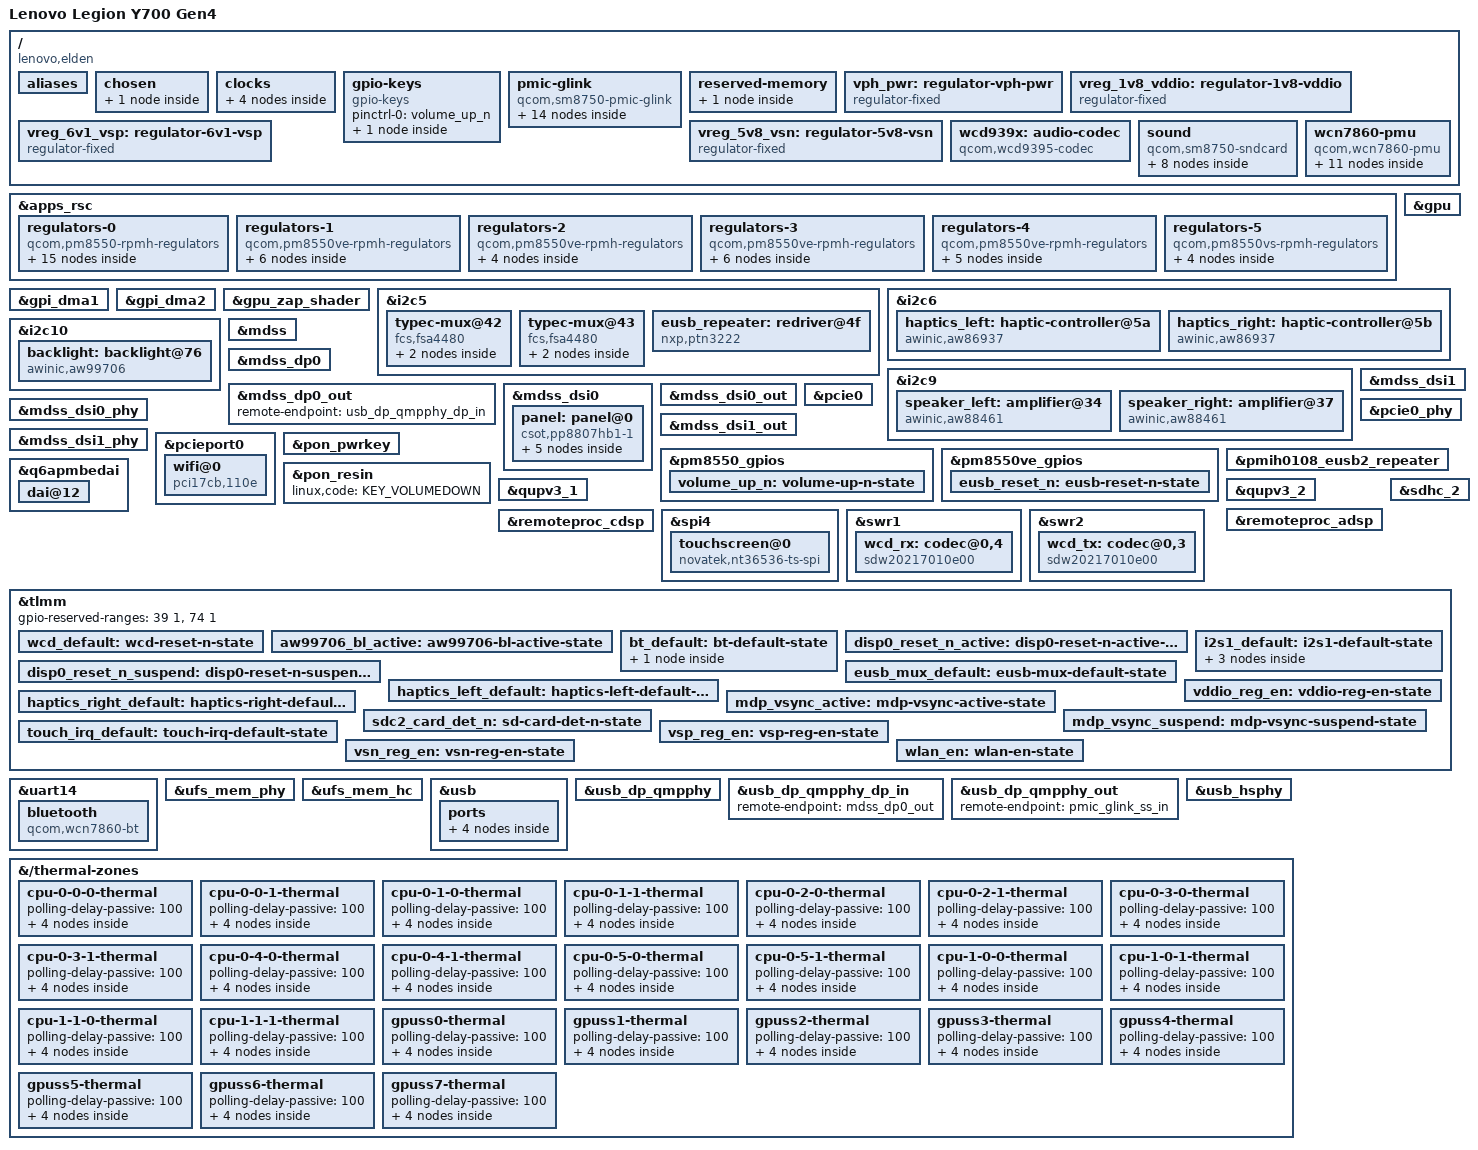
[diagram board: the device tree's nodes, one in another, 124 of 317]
// SPDX-License-Identifier: BSD-3-Clause
/*
 * Copyright (c) 2024 Qualcomm Innovation Center, Inc. All rights reserved.
 * Copyright (c) 2025-2026 Pengyu Luo <mitltlatltl@gmail.com>
 */

/*
 * based on https://lore.kernel.org/linux-arm-msm/20260726143048.130116-1-mitltlatltl@gmail.com/
 * with some modifications.
 */

/dts-v1/;

#include <dt-bindings/gpio/gpio.h>
#include <dt-bindings/phy/phy.h>
#include <dt-bindings/regulator/qcom,rpmh-regulator.h>
#include "sm8750.dtsi"
#include "pm8550.dtsi"
#define PMK8550VE_SID 8
#include "pm8550ve.dtsi"
#include "pmih0108.dtsi"
#include "pmk8550.dtsi"
#include "sm8750-pmics.dtsi"

/ {
	model = "Lenovo Legion Y700 Gen4";
	compatible = "lenovo,elden", "qcom,sm8750";
	chassis-type = "tablet";

	aliases {
		i2c5 = &i2c5;
		i2c6 = &i2c6;
		i2c9 = &i2c9;
		i2c10 = &i2c10;
		serial1 = &uart14;
	};

	/* mandatory, ABL requires the chosen node (not the fb) to boot */
	chosen {
		#address-cells = <2>;
		#size-cells = <2>;
		ranges;

		framebuffer: framebuffer@fc800000 {
			compatible = "simple-framebuffer";
			reg = <0x0 0xfc800000 0x0 0x2b00000>;
			width = <1904>;
			height = <3040>;
			stride = <(1904 * 4)>;
			format = "a8r8g8b8";
		};
	};

	clocks {
		xo_board: xo-board {
			compatible = "fixed-clock";
			clock-frequency = <76800000>;
			#clock-cells = <0>;
		};

		sleep_clk: sleep-clk {
			compatible = "fixed-clock";
			clock-frequency = <32000>;
			#clock-cells = <0>;
		};

		bi_tcxo_div2: bi-tcxo-div2-clk {
			compatible = "fixed-factor-clock";
			#clock-cells = <0>;

			clocks = <&rpmhcc RPMH_CXO_CLK>;
			clock-mult = <1>;
			clock-div = <2>;
		};

		bi_tcxo_ao_div2: bi-tcxo-ao-div2-clk {
			compatible = "fixed-factor-clock";
			#clock-cells = <0>;

			clocks = <&rpmhcc RPMH_CXO_CLK_A>;
			clock-mult = <1>;
			clock-div = <2>;
		};
	};

	gpio-keys {
		compatible = "gpio-keys";

		pinctrl-0 = <&volume_up_n>;
		pinctrl-names = "default";

		key-volume-up {
			label = "Volume Up";
			linux,code = <KEY_VOLUMEUP>;
			gpios = <&pm8550_gpios 6 GPIO_ACTIVE_LOW>;
			debounce-interval = <15>;
			linux,can-disable;
			wakeup-source;
		};
	};

	pmic-glink {
		compatible = "qcom,sm8750-pmic-glink",
			     "qcom,sm8550-pmic-glink",
			     "qcom,pmic-glink";
		#address-cells = <1>;
		#size-cells = <0>;
		orientation-gpios = <&tlmm 61 GPIO_ACTIVE_HIGH>;
		/* Firmware reports negative current while charging. */
		qcom,battery-current-inverted;

		/* Long edge */
		connector@0 {
			compatible = "usb-c-connector";
			reg = <0>;

			power-role = "dual";
			data-role = "dual";

			ports {
				#address-cells = <1>;
				#size-cells = <0>;

				port@0 {
					reg = <0>;

					pmic_glink_hs_in: endpoint {
						remote-endpoint = <&usb_dwc3_hs>;
					};
				};

				port@1 {
					reg = <1>;

					pmic_glink_ss_in: endpoint {
						remote-endpoint = <&usb_dp_qmpphy_out>;
					};
				};

				port@2 {
					reg = <2>;

					pmic_glink_sbu: endpoint {
						remote-endpoint = <&fsa4480_sbu_mux>;
					};
				};
			};
		};

		/* Short edge */
		connector@1 {
			compatible = "usb-c-connector";
			reg = <1>;

			power-role = "dual";
			data-role = "dual";

			ports {
				#address-cells = <1>;
				#size-cells = <0>;

				port@0 {
					reg = <0>;

					pmic_glink_hs_c2_in: endpoint {
						remote-endpoint = <&usb_dwc3_hs2>;
					};
				};

				port@1 {
					reg = <1>;

					pmic_glink_hs_sbu: endpoint {
						remote-endpoint = <&fsa4480_hs_sbu_mux>;
					};
				};
			};
		};
	};

	reserved-memory {
		/*
		 * Use this to tell the BL to initialize the display related
		 * resources, so we can use efifb. Please 's/-/_/'
		 */
		splash-region@fc800000 {
			reg = <0 0xfc800000 0 0x2b00000>;
			no-map;
		};
	};

	vph_pwr: regulator-vph-pwr {
		compatible = "regulator-fixed";

		regulator-name = "vph_pwr";
		regulator-min-microvolt = <3700000>;
		regulator-max-microvolt = <3700000>;

		regulator-always-on;
		regulator-boot-on;
	};

	vreg_1v8_vddio: regulator-1v8-vddio {
		compatible = "regulator-fixed";

		regulator-name = "vreg_1v8_vddio";
		regulator-min-microvolt = <1800000>;
		regulator-max-microvolt = <1800000>;

		gpio = <&tlmm 161 GPIO_ACTIVE_HIGH>;
		enable-active-high;

		pinctrl-0 = <&vddio_reg_en>;
		pinctrl-names = "default";

		regulator-always-on;
		regulator-boot-on;
	};

	vreg_6v1_vsp: regulator-6v1-vsp {
		compatible = "regulator-fixed";

		regulator-name = "vreg_6v1_vsp";
		regulator-min-microvolt = <6100000>;
		regulator-max-microvolt = <6100000>;

		gpio = <&tlmm 72 GPIO_ACTIVE_HIGH>;
		enable-active-high;

		pinctrl-0 = <&vsp_reg_en>;
		pinctrl-names = "default";

		regulator-always-on;
		regulator-boot-on;
	};

	vreg_5v8_vsn: regulator-5v8-vsn {
		compatible = "regulator-fixed";

		regulator-name = "vreg_5v8_vsn";
		regulator-min-microvolt = <5800000>;
		regulator-max-microvolt = <5800000>;

		gpio = <&tlmm 73 GPIO_ACTIVE_HIGH>;
		enable-active-high;

		pinctrl-0 = <&vsn_reg_en>;
		pinctrl-names = "default";

		regulator-always-on;
		regulator-boot-on;
	};

	wcd939x: audio-codec {
		compatible = "qcom,wcd9395-codec", "qcom,wcd9390-codec";
		pinctrl-0 = <&wcd_default>;
		pinctrl-names = "default";
		reset-gpios = <&tlmm 101 GPIO_ACTIVE_LOW>;

		vdd-buck-supply = <&vreg_l15b_1p8>;
		vdd-rxtx-supply = <&vreg_l15b_1p8>;
		vdd-io-supply = <&vreg_l15b_1p8>;
		vdd-px-supply = <&vreg_l15b_1p8>;
		vdd-mic-bias-supply = <&vreg_bob1>;

		/* Microphone bias voltages from the stock board configuration. */
		qcom,micbias1-microvolt = <2000000>;
		qcom,micbias2-microvolt = <2700000>;
		qcom,micbias3-microvolt = <1800000>;
		qcom,micbias4-microvolt = <2000000>;
		qcom,mbhc-buttons-vthreshold-microvolt = <75000 150000 237000 500000
							500000 500000 500000 500000>;
		qcom,mbhc-headset-vthreshold-microvolt = <1700000>;
		qcom,mbhc-headphone-vthreshold-microvolt = <50000>;
		qcom,rx-device = <&wcd_rx>;
		qcom,tx-device = <&wcd_tx>;
		#sound-dai-cells = <1>;
	};

	sound {
		compatible = "qcom,sm8750-sndcard", "qcom,sm8450-sndcard";

		pinctrl-names = "default";
		pinctrl-0 = <&i2s1_default>;

		model = "Lenovo-Y700-Gen4";
		widgets = "Speaker", "Left Speaker", "Speaker", "Right Speaker";
		audio-routing = "Left Speaker", "Left OUT",
				"Right Speaker", "Right OUT",
				"AMIC1", "MIC BIAS1",
				"AMIC2", "MIC BIAS2",
				"AMIC3", "MIC BIAS3",
				"AMIC4", "MIC BIAS4",
				"AMIC5", "MIC BIAS4",
				"TX SWR_INPUT0", "ADC1_OUTPUT",
				"TX SWR_INPUT1", "ADC2_OUTPUT",
				"TX SWR_INPUT2", "ADC3_OUTPUT",
				"TX SWR_INPUT3", "ADC4_OUTPUT";

		mi2s-dai-link {
			link-name = "Secondary MI2S";

			cpu {
				sound-dai = <&q6apmbedai SECONDARY_MI2S_RX>;
			};

			codec {
				sound-dai = <&speaker_left>, <&speaker_right>;
			};

			platform {
				sound-dai = <&q6apm>;
			};
		};

		wcd-capture-dai-link {
			link-name = "WCD Capture";

			cpu {
				sound-dai = <&q6apmbedai TX_CODEC_DMA_TX_3>;
			};

			codec {
				sound-dai = <&wcd939x 1>, <&swr2 0>, <&lpass_txmacro 0>;
			};

			platform {
				sound-dai = <&q6apm>;
			};
		};
	};

	wcn7860-pmu {
		compatible = "qcom,wcn7860-pmu";

		pinctrl-names = "default";
		pinctrl-0 = <&wlan_en>, <&bt_default>;

		wlan-enable-gpios = <&tlmm 16 GPIO_ACTIVE_HIGH>;
		bt-enable-gpios = <&pm8550ve_f_gpios 3 GPIO_ACTIVE_HIGH>;

		vddio-supply = <&vreg_l3f_1p8>;
		vddio1p2-supply = <&vreg_l2f_1p2>;
		vddaon-supply = <&vreg_s4d_0p85>;
		vdddig-supply = <&vreg_s5f_0p5>;
		vddrfa1p2-supply = <&vreg_s7i_1p2>;
		vddrfa1p8-supply = <&vreg_s3g_1p8>;

		clocks = <&rpmhcc RPMH_RF_CLK1>;

		regulators {
			vreg_pmu_rfa_cmn: ldo0 {
				regulator-name = "vreg_pmu_rfa_cmn";
			};

			vreg_pmu_aon_0p59: ldo1 {
				regulator-name = "vreg_pmu_aon_0p59";
			};

			vreg_pmu_wlcx_0p8: ldo2 {
				regulator-name = "vreg_pmu_wlcx_0p8";
			};

			vreg_pmu_wlmx_0p85: ldo3 {
				regulator-name = "vreg_pmu_wlmx_0p85";
			};

			vreg_pmu_btcmx_0p85: ldo4 {
				regulator-name = "vreg_pmu_btcmx_0p85";
			};

			vreg_pmu_rfa_0p8: ldo5 {
				regulator-name = "vreg_pmu_rfa_0p8";
			};

			vreg_pmu_rfa_1p2: ldo6 {
				regulator-name = "vreg_pmu_rfa_1p2";
			};

			vreg_pmu_rfa_1p8: ldo7 {
				regulator-name = "vreg_pmu_rfa_1p8";
			};

			vreg_pmu_pcie_0p9: ldo8 {
				regulator-name = "vreg_pmu_pcie_0p9";
			};

			vreg_pmu_pcie_1p8: ldo9 {
				regulator-name = "vreg_pmu_pcie_1p8";
			};
		};
	};
};

&apps_rsc {
	regulators-0 {
		compatible = "qcom,pm8550-rpmh-regulators";

		vdd-bob1-supply = <&vph_pwr>;
		vdd-bob2-supply = <&vph_pwr>;
		vdd-l1-l4-l10-supply = <&vreg_s3g_1p8>;
		vdd-l2-l13-l14-supply = <&vreg_bob1>;
		vdd-l3-supply = <&vreg_s7i_1p2>;
		vdd-l5-l16-supply = <&vreg_bob1>;
		vdd-l6-l7-supply = <&vreg_bob1>;
		vdd-l8-l9-supply = <&vreg_bob1>;
		vdd-l11-supply = <&vreg_s7i_1p2>;
		vdd-l12-supply = <&vreg_s3g_1p8>;
		vdd-l15-supply = <&vreg_s3g_1p8>;
		vdd-l17-supply = <&vreg_bob2>;

		qcom,pmic-id = "b";

		vreg_bob1: bob1 {
			regulator-name = "vreg_bob1";
			regulator-min-microvolt = <3008000>;
			regulator-max-microvolt = <4000000>;
			regulator-initial-mode = <RPMH_REGULATOR_MODE_HPM>;
		};

		vreg_bob2: bob2 {
			regulator-name = "vreg_bob2";
			regulator-min-microvolt = <2704000>;
			regulator-max-microvolt = <3008000>;
			regulator-initial-mode = <RPMH_REGULATOR_MODE_HPM>;
		};

		vreg_l1b_1p8: ldo1 {
			regulator-name = "vreg_l1b_1p8";
			regulator-min-microvolt = <1800000>;
			regulator-max-microvolt = <1800000>;
			regulator-initial-mode = <RPMH_REGULATOR_MODE_HPM>;
			regulator-allow-set-load;
			regulator-allowed-modes = <RPMH_REGULATOR_MODE_LPM
						   RPMH_REGULATOR_MODE_HPM>;
		};

		vreg_l2b_3p0: ldo2 {
			regulator-name = "vreg_l2b_3p0";
			regulator-min-microvolt = <3008000>;
			regulator-max-microvolt = <3048000>;
			regulator-initial-mode = <RPMH_REGULATOR_MODE_HPM>;
			regulator-allow-set-load;
			regulator-allowed-modes = <RPMH_REGULATOR_MODE_LPM
						   RPMH_REGULATOR_MODE_HPM>;
		};

		vreg_l4b_1p8: ldo4 {
			regulator-name = "vreg_l4b_1p8";
			regulator-min-microvolt = <1800000>;
			regulator-max-microvolt = <1800000>;
			regulator-initial-mode = <RPMH_REGULATOR_MODE_HPM>;
			regulator-allow-set-load;
			regulator-allowed-modes = <RPMH_REGULATOR_MODE_LPM
						   RPMH_REGULATOR_MODE_HPM>;
		};

		vreg_l5b_3p1: ldo5 {
			regulator-name = "vreg_l5b_3p1";
			regulator-min-microvolt = <3100000>;
			regulator-max-microvolt = <3148000>;
			regulator-initial-mode = <RPMH_REGULATOR_MODE_HPM>;
			regulator-allow-set-load;
			regulator-allowed-modes = <RPMH_REGULATOR_MODE_LPM
						   RPMH_REGULATOR_MODE_HPM>;
		};

		vreg_l6b_1p8: ldo6 {
			regulator-name = "vreg_l6b_1p8";
			regulator-min-microvolt = <1800000>;
			regulator-max-microvolt = <3008000>;
			regulator-initial-mode = <RPMH_REGULATOR_MODE_HPM>;
			regulator-allow-set-load;
			regulator-allowed-modes = <RPMH_REGULATOR_MODE_LPM
						   RPMH_REGULATOR_MODE_HPM>;
		};

		vreg_l7b_1p8: ldo7 {
			regulator-name = "vreg_l7b_1p8";
			regulator-min-microvolt = <1800000>;
			regulator-max-microvolt = <3008000>;
			regulator-initial-mode = <RPMH_REGULATOR_MODE_HPM>;
			regulator-allow-set-load;
			regulator-allowed-modes = <RPMH_REGULATOR_MODE_LPM
						   RPMH_REGULATOR_MODE_HPM>;
		};

		vreg_l8b_1p8: ldo8 {
			regulator-name = "vreg_l8b_1p8";
			regulator-min-microvolt = <1800000>;
			regulator-max-microvolt = <3008000>;
			regulator-initial-mode = <RPMH_REGULATOR_MODE_HPM>;
			regulator-allow-set-load;
			regulator-allowed-modes = <RPMH_REGULATOR_MODE_LPM
						   RPMH_REGULATOR_MODE_HPM>;
		};

		vreg_l9b_2p9: ldo9 {
			regulator-name = "vreg_l9b_2p9";
			regulator-min-microvolt = <2960000>;
			regulator-max-microvolt = <3008000>;
			regulator-initial-mode = <RPMH_REGULATOR_MODE_HPM>;
			regulator-allow-set-load;
			regulator-allowed-modes = <RPMH_REGULATOR_MODE_LPM
						   RPMH_REGULATOR_MODE_HPM>;
		};

		vreg_l10b_1p8: ldo10 {
			regulator-name = "vreg_l10b_1p8";
			regulator-min-microvolt = <1800000>;
			regulator-max-microvolt = <1800000>;
			regulator-initial-mode = <RPMH_REGULATOR_MODE_HPM>;
			regulator-allow-set-load;
			regulator-allowed-modes = <RPMH_REGULATOR_MODE_LPM
						   RPMH_REGULATOR_MODE_HPM>;
		};

		vreg_l14b_3p2: ldo14 {
			regulator-name = "vreg_l14b_3p2";
			regulator-min-microvolt = <3200000>;
			regulator-max-microvolt = <3200000>;
			regulator-initial-mode = <RPMH_REGULATOR_MODE_HPM>;
			regulator-allow-set-load;
			regulator-allowed-modes = <RPMH_REGULATOR_MODE_LPM
						   RPMH_REGULATOR_MODE_HPM>;
		};

		vreg_l15b_1p8: ldo15 {
			regulator-name = "vreg_l15b_1p8";
			regulator-min-microvolt = <1800000>;
			regulator-max-microvolt = <1800000>;
			regulator-initial-mode = <RPMH_REGULATOR_MODE_HPM>;
			regulator-allow-set-load;
			regulator-allowed-modes = <RPMH_REGULATOR_MODE_LPM
						   RPMH_REGULATOR_MODE_HPM>;
		};

		vreg_l16b_2p8: ldo16 {
			regulator-name = "vreg_l16b_2p8";
			regulator-min-microvolt = <2800000>;
			regulator-max-microvolt = <2800000>;
			regulator-initial-mode = <RPMH_REGULATOR_MODE_HPM>;
			regulator-allow-set-load;
			regulator-allowed-modes = <RPMH_REGULATOR_MODE_LPM
						   RPMH_REGULATOR_MODE_HPM>;
		};

		vreg_l17b_2p5: ldo17 {
			regulator-name = "vreg_l17b_2p5";
			regulator-min-microvolt = <2504000>;
			regulator-max-microvolt = <2504000>;
			regulator-initial-mode = <RPMH_REGULATOR_MODE_HPM>;
			regulator-allow-set-load;
			regulator-allowed-modes = <RPMH_REGULATOR_MODE_LPM
						   RPMH_REGULATOR_MODE_HPM>;
		};
	};

	regulators-1 {
		compatible = "qcom,pm8550ve-rpmh-regulators";

		vdd-l1-supply = <&vreg_s7i_1p2>;
		vdd-l2-supply = <&vreg_s1d_0p97>;
		vdd-l3-supply = <&vreg_s1d_0p97>;
		vdd-s1-supply = <&vph_pwr>;
		vdd-s3-supply = <&vph_pwr>;
		vdd-s4-supply = <&vph_pwr>;

		qcom,pmic-id = "d";

		vreg_s1d_0p97: smps1 {
			regulator-name = "vreg_s1d_0p97";
			regulator-min-microvolt = <880000>;
			regulator-max-microvolt = <1100000>;
			regulator-initial-mode = <RPMH_REGULATOR_MODE_HPM>;
		};

		vreg_s3d_1p2: smps3 {
			regulator-name = "vreg_s3d_1p2";
			regulator-min-microvolt = <1200000>;
			regulator-max-microvolt = <1300000>;
			regulator-initial-mode = <RPMH_REGULATOR_MODE_HPM>;
		};

		vreg_s4d_0p85: smps4 {
			regulator-name = "vreg_s4d_0p85";
			regulator-min-microvolt = <500000>;
			regulator-max-microvolt = <1036000>;
			regulator-initial-mode = <RPMH_REGULATOR_MODE_HPM>;
		};

		vreg_l1d_1p2: ldo1 {
			regulator-name = "vreg_l1d_1p2";
			regulator-min-microvolt = <1200000>;
			regulator-max-microvolt = <1200000>;
			regulator-initial-mode = <RPMH_REGULATOR_MODE_HPM>;
			regulator-allow-set-load;
			regulator-allowed-modes = <RPMH_REGULATOR_MODE_LPM
						   RPMH_REGULATOR_MODE_HPM>;
		};

		vreg_l2d_0p88: ldo2 {
			regulator-name = "vreg_l2d_0p88";
			regulator-min-microvolt = <880000>;
			regulator-max-microvolt = <912000>;
			regulator-initial-mode = <RPMH_REGULATOR_MODE_HPM>;
			regulator-allow-set-load;
			regulator-allowed-modes = <RPMH_REGULATOR_MODE_LPM
						   RPMH_REGULATOR_MODE_HPM>;
		};

		vreg_l3d_0p88: ldo3 {
			regulator-name = "vreg_l3d_0p88";
			regulator-min-microvolt = <880000>;
			regulator-max-microvolt = <920000>;
			regulator-initial-mode = <RPMH_REGULATOR_MODE_HPM>;
			regulator-allow-set-load;
			regulator-allowed-modes = <RPMH_REGULATOR_MODE_LPM
						   RPMH_REGULATOR_MODE_HPM>;
		};
	};

	regulators-2 {
		compatible = "qcom,pm8550ve-rpmh-regulators";

		vdd-l1-supply = <&vreg_s1d_0p97>;
		vdd-l2-supply = <&vreg_s7i_1p2>;
		vdd-l3-supply = <&vreg_s3g_1p8>;
		vdd-s5-supply = <&vph_pwr>;

		qcom,pmic-id = "f";

		vreg_s5f_0p5: smps5 {
			regulator-name = "vreg_s5f_0p5";
			regulator-min-microvolt = <500000>;
			regulator-max-microvolt = <1000000>;
			regulator-initial-mode = <RPMH_REGULATOR_MODE_HPM>;
		};

		vreg_l1f_0p88: ldo1 {
			regulator-name = "vreg_l1f_0p88";
			regulator-min-microvolt = <880000>;
			regulator-max-microvolt = <920000>;
			regulator-initial-mode = <RPMH_REGULATOR_MODE_HPM>;
			regulator-allow-set-load;
			regulator-allowed-modes = <RPMH_REGULATOR_MODE_LPM
						   RPMH_REGULATOR_MODE_HPM>;
		};

		vreg_l2f_1p2: ldo2 {
			regulator-name = "vreg_l2f_1p2";
			regulator-min-microvolt = <1200000>;
			regulator-max-microvolt = <1200000>;
			regulator-initial-mode = <RPMH_REGULATOR_MODE_HPM>;
			regulator-allow-set-load;
			regulator-allowed-modes = <RPMH_REGULATOR_MODE_LPM
						   RPMH_REGULATOR_MODE_HPM>;
		};

		vreg_l3f_1p8: ldo3 {
			regulator-name = "vreg_l3f_1p8";
			regulator-min-microvolt = <1800000>;
			regulator-max-microvolt = <1800000>;
			regulator-initial-mode = <RPMH_REGULATOR_MODE_HPM>;
			regulator-allow-set-load;
			regulator-allowed-modes = <RPMH_REGULATOR_MODE_LPM
						   RPMH_REGULATOR_MODE_HPM>;
		};

	};

	regulators-3 {
		compatible = "qcom,pm8550ve-rpmh-regulators";

		vdd-l1-supply = <&vreg_s1d_0p97>;
		vdd-l2-supply = <&vreg_s3g_1p8>;
		vdd-l3-supply = <&vreg_s7i_1p2>;
		vdd-s1-supply = <&vph_pwr>;
		vdd-s3-supply = <&vph_pwr>;

		qcom,pmic-id = "g";

		vreg_s1g_0p5: smps1 {
			regulator-name = "vreg_s1g_0p5";
			regulator-min-microvolt = <300000>;
			regulator-max-microvolt = <700000>;
			regulator-initial-mode = <RPMH_REGULATOR_MODE_HPM>;
		};

		vreg_s3g_1p8: smps3 {
			regulator-name = "vreg_s3g_1p8";
			regulator-min-microvolt = <1856000>;
			regulator-max-microvolt = <2000000>;
			regulator-initial-mode = <RPMH_REGULATOR_MODE_LPM>;
			regulator-allow-set-load;
			regulator-allowed-modes = <RPMH_REGULATOR_MODE_LPM
						   RPMH_REGULATOR_MODE_HPM>;
		};

		vreg_s4g_0p75: smps4 {
			regulator-name = "vreg_s4g_0p75";
			regulator-min-microvolt = <300000>;
			regulator-max-microvolt = <900000>;
			regulator-initial-mode = <RPMH_REGULATOR_MODE_HPM>;
		};

		vreg_l1g_0p91: ldo1 {
			regulator-name = "vreg_l1g_0p91";
			regulator-min-microvolt = <912000>;
			regulator-max-microvolt = <936000>;
			regulator-initial-mode = <RPMH_REGULATOR_MODE_HPM>;
			regulator-allow-set-load;
			regulator-allowed-modes = <RPMH_REGULATOR_MODE_LPM
						   RPMH_REGULATOR_MODE_HPM>;
		};

		vreg_l2g_1p8: ldo2 {
			regulator-name = "vreg_l2g_1p8";
			regulator-min-microvolt = <1200000>;
			regulator-max-microvolt = <1860000>;
			regulator-initial-mode = <RPMH_REGULATOR_MODE_HPM>;
			regulator-allow-set-load;
			regulator-allowed-modes = <RPMH_REGULATOR_MODE_LPM
						   RPMH_REGULATOR_MODE_HPM>;
		};

		vreg_l3g_1p2: ldo3 {
			regulator-name = "vreg_l3g_1p2";
			regulator-min-microvolt = <1200000>;
			regulator-max-microvolt = <1256000>;
			regulator-initial-mode = <RPMH_REGULATOR_MODE_HPM>;
			regulator-allow-set-load;
			regulator-allowed-modes = <RPMH_REGULATOR_MODE_LPM
						   RPMH_REGULATOR_MODE_HPM>;
		};
	};

	regulators-4 {
		compatible = "qcom,pm8550ve-rpmh-regulators";

		vdd-l1-supply = <&vreg_s7i_1p2>;
		vdd-l2-supply = <&vreg_s7i_1p2>;
		vdd-l3-supply = <&vreg_s1d_0p97>;
		vdd-s7-supply = <&vph_pwr>;
		vdd-s8-supply = <&vph_pwr>;

		qcom,pmic-id = "i";

		vreg_s7i_1p2: smps7 {
			regulator-name = "vreg_s7i_1p2";
			regulator-min-microvolt = <1224000>;
			regulator-max-microvolt = <1340000>;
			regulator-initial-mode = <RPMH_REGULATOR_MODE_HPM>;
		};

		vreg_s8i_0p9: smps8 {
			regulator-name = "vreg_s8i_0p9";
			regulator-min-microvolt = <900000>;
			regulator-max-microvolt = <972000>;
			regulator-initial-mode = <RPMH_REGULATOR_MODE_HPM>;
		};

		vreg_l1i_1p2: ldo1 {
			regulator-name = "vreg_l1i_1p2";
			regulator-min-microvolt = <1200000>;
			regulator-max-microvolt = <1200000>;
			regulator-initial-mode = <RPMH_REGULATOR_MODE_HPM>;
			regulator-allow-set-load;
			regulator-allowed-modes = <RPMH_REGULATOR_MODE_LPM
						   RPMH_REGULATOR_MODE_HPM>;
		};

		vreg_l2i_1p2: ldo2 {
			regulator-name = "vreg_l2i_1p2";
			regulator-min-microvolt = <1200000>;
			regulator-max-microvolt = <1200000>;
			regulator-initial-mode = <RPMH_REGULATOR_MODE_HPM>;
			regulator-allow-set-load;
			regulator-allowed-modes = <RPMH_REGULATOR_MODE_LPM
						   RPMH_REGULATOR_MODE_HPM>;
		};

		vreg_l3i_0p88: ldo3 {
			regulator-name = "vreg_l3i_0p88";
			regulator-min-microvolt = <880000>;
			regulator-max-microvolt = <912000>;
			regulator-initial-mode = <RPMH_REGULATOR_MODE_HPM>;
			regulator-allow-set-load;
			regulator-allowed-modes = <RPMH_REGULATOR_MODE_LPM
						   RPMH_REGULATOR_MODE_HPM>;
		};
	};

	regulators-5 {
		compatible = "qcom,pm8550vs-rpmh-regulators";

		vdd-l1-supply = <&vreg_s1d_0p97>;
		vdd-l2-supply = <&vreg_s7i_1p2>;
		vdd-s2-supply = <&vph_pwr>;
		vdd-s3-supply = <&vph_pwr>;

		qcom,pmic-id = "j";

		vreg_s2j_1p1: smps2 {
			regulator-name = "vreg_s2j_1p1";
			regulator-min-microvolt = <1000000>;
			regulator-max-microvolt = <1100000>;
			regulator-initial-mode = <RPMH_REGULATOR_MODE_HPM>;
		};

		vreg_s3j_1p1: smps3 {
			regulator-name = "vreg_s3j_1p1";
			regulator-min-microvolt = <1000000>;
			regulator-max-microvolt = <1100000>;
			regulator-initial-mode = <RPMH_REGULATOR_MODE_HPM>;
		};

		vreg_l1j_0p91: ldo1 {
			regulator-name = "vreg_l1j_0p91";
			regulator-min-microvolt = <880000>;
			regulator-max-microvolt = <920000>;
			regulator-initial-mode = <RPMH_REGULATOR_MODE_HPM>;
			regulator-allow-set-load;
			regulator-allowed-modes = <RPMH_REGULATOR_MODE_LPM
						   RPMH_REGULATOR_MODE_HPM>;
		};

		vreg_l2j_1p2: ldo2 {
			regulator-name = "vreg_l2j_1p2";
			regulator-min-microvolt = <1200000>;
			regulator-max-microvolt = <1200000>;
			regulator-initial-mode = <RPMH_REGULATOR_MODE_HPM>;
			regulator-allow-set-load;
			regulator-allowed-modes = <RPMH_REGULATOR_MODE_LPM
						   RPMH_REGULATOR_MODE_HPM>;
		};
	};
};

&gpi_dma1 {
	status = "okay";
};

&gpi_dma2 {
	status = "okay";
};

&gpu {
	status = "okay";
};

&gpu_zap_shader {
	firmware-name = "qcom/sm8750/LENOVO/elden/gen80000_zap.mbn";
};

&i2c5 {
	status = "okay";

	typec-mux@42 {
		compatible = "fcs,fsa4480";
		reg = <0x42>;

		vcc-supply = <&vreg_bob1>;

		mode-switch;
		orientation-switch;

		port {
			fsa4480_hs_sbu_mux: endpoint {
				remote-endpoint = <&pmic_glink_hs_sbu>;
			};
		};
	};

	typec-mux@43 {
		compatible = "fcs,fsa4480";
		reg = <0x43>;

		vcc-supply = <&vreg_bob1>;

		mode-switch;
		orientation-switch;

		port {
			fsa4480_sbu_mux: endpoint {
				remote-endpoint = <&pmic_glink_sbu>;
			};
		};
	};

	eusb_repeater: redriver@4f {
		compatible = "nxp,ptn3222"; /* PTN3222DUK */
		reg = <0x4f>;
		#phy-cells = <0>;

		vdd3v3-supply = <&vreg_l5b_3p1>;
		vdd1v8-supply = <&vreg_l15b_1p8>;

		reset-gpios = <&pm8550ve_gpios 6 GPIO_ACTIVE_LOW>;

		pinctrl-0 = <&eusb_reset_n>, <&eusb_mux_default>;
		pinctrl-names = "default";
	};
};

&i2c6 {
	status = "okay";

	haptics_left: haptic-controller@5a {
		compatible = "awinic,aw86937";
		reg = <0x5a>;

		interrupts-extended = <&tlmm 99 IRQ_TYPE_EDGE_FALLING>;
		reset-gpios = <&tlmm 127 GPIO_ACTIVE_LOW>;

		pinctrl-0 = <&haptics_left_default>;
		pinctrl-names = "default";

		firmware-name = "awinic/awinic_aw86937_lenovo_elden_ram.bin";
		/* Loop the stock RAM image's sustained vibration waveform. */
		awinic,ram-waveform-index = <4>;
	};

	haptics_right: haptic-controller@5b {
		compatible = "awinic,aw86937";
		reg = <0x5b>;

		interrupts-extended = <&tlmm 95 IRQ_TYPE_EDGE_FALLING>;
		reset-gpios = <&tlmm 119 GPIO_ACTIVE_LOW>;

		pinctrl-0 = <&haptics_right_default>;
		pinctrl-names = "default";

		firmware-name = "awinic/awinic_aw86937_lenovo_elden_ram.bin";
		awinic,ram-waveform-index = <4>;
	};
};

&i2c9 {
	status = "okay";

	speaker_left: amplifier@34 {
		compatible = "awinic,aw88461";
		reg = <0x34>;

		#sound-dai-cells = <0>;

		reset-gpios = <&tlmm 120 GPIO_ACTIVE_LOW>;
		firmware-name = "awinic/awinic_aw88461_lenovo_elden.bin";
		awinic,audio-channel = <0>;
		sound-name-prefix = "Left";
	};

	speaker_right: amplifier@37 {
		compatible = "awinic,aw88461";
		reg = <0x37>;

		#sound-dai-cells = <0>;

		reset-gpios = <&tlmm 128 GPIO_ACTIVE_LOW>;
		firmware-name = "awinic/awinic_aw88461_lenovo_elden.bin";
		awinic,audio-channel = <1>;
		sound-name-prefix = "Right";
	};
};

&i2c10 {
	status = "okay";

	/* i2c_wl2868c@2F */

	/*
	 * bias@3e, as9702 or aw37504
	 *
	 * gpio72/gpio73: enable pin for OUTP/OUTN
	 * In practical, register programming is not required for as9702
	 *
	 * as9702: (REG02H[7:0]=0xf1)
	 * reg: 0x00 0x01 0x03
	 * val: 0x15 0x12 0x73
	 *
	 * aw37504: (REG04H[1:0]=0x01)
	 * reg: 0x00 0x01 0x03 0x04
	 * val: 0x15 0x12 0x43 0x09
	 */

	backlight: backlight@76 {
		compatible = "awinic,aw99706";
		reg = <0x76>;

		enable-gpio = <&tlmm 88 GPIO_ACTIVE_HIGH>;

		pinctrl-0 = <&aw99706_bl_active>;
		pinctrl-names = "default";

		default-brightness = <511>;
		max-brightness = <4095>;

		awinic,dim-mode = <1>;
		awinic,sw-freq-hz = <750000>;
		awinic,sw-ilmt-microamp = <3000000>;
		awinic,uvlo-thres-microvolt = <2200000>;
		awinic,iled-max-microamp = <30000>;
		awinic,ramp-ctl = <3>;
	};
};

&mdss {
	status = "okay";
};

&mdss_dp0 {
	status = "okay";
};

&mdss_dp0_out {
	remote-endpoint = <&usb_dp_qmpphy_dp_in>;
};

&mdss_dsi0 {
	vdda-supply = <&vreg_l3g_1p2>;

	qcom,dual-dsi-mode;
	qcom,sync-dual-dsi;
	qcom,master-dsi;

	status = "okay";

	panel: panel@0 {
		compatible = "csot,pp8807hb1-1", "novatek,nt36536";
		reg = <0>;

		reset-gpios = <&tlmm 98 GPIO_ACTIVE_LOW>;

		vddio-supply = <&vreg_1v8_vddio>;
		vsp-supply = <&vreg_6v1_vsp>;
		vsn-supply = <&vreg_5v8_vsn>;

		pinctrl-0 = <&disp0_reset_n_active>, <&mdp_vsync_active>;
		pinctrl-1 = <&disp0_reset_n_suspend>, <&mdp_vsync_suspend>;
		pinctrl-names = "default", "sleep";

		backlight = <&backlight>;

		ports {
			#address-cells = <1>;
			#size-cells = <0>;

			port@0 {
				reg = <0>;

				panel_in_0: endpoint {
					remote-endpoint = <&mdss_dsi0_out>;
				};
			};

			port@1 {
				reg = <1>;

				panel_in_1: endpoint {
					remote-endpoint = <&mdss_dsi1_out>;
				};
			};
		};
	};
};

&mdss_dsi0_out {
	remote-endpoint = <&panel_in_0>;
	data-lanes = <0 1 2>;
};

&mdss_dsi0_phy {
	vdds-supply = <&vreg_l3i_0p88>;
	phy-type = <PHY_TYPE_CPHY>;

	status = "okay";
};

&mdss_dsi1 {
	/* Bonded DSI, source to dsi0_phy PLL */
	clocks = <&dispcc DISP_CC_MDSS_BYTE1_CLK>,
		 <&dispcc DISP_CC_MDSS_BYTE1_INTF_CLK>,
		 <&dispcc DISP_CC_MDSS_PCLK1_CLK>,
		 <&dispcc DISP_CC_MDSS_ESC1_CLK>,
		 <&dispcc DISP_CC_MDSS_AHB_CLK>,
		 <&gcc GCC_DISP_HF_AXI_CLK>,
		 <&mdss_dsi0_phy DSI_PIXEL_PLL_CLK>,
		 <&mdss_dsi0_phy DSI_BYTE_PLL_CLK>,
		 <&dispcc DISP_CC_ESYNC1_CLK>,
		 <&dispcc DISP_CC_OSC_CLK>,
		 <&dispcc DISP_CC_MDSS_BYTE1_CLK_SRC>,
		 <&dispcc DISP_CC_MDSS_PCLK1_CLK_SRC>;

	vdda-supply = <&vreg_l3g_1p2>;

	qcom,dual-dsi-mode;
	qcom,sync-dual-dsi;

	status = "okay";
};

&mdss_dsi1_out {
	remote-endpoint = <&panel_in_1>;
	data-lanes = <0 1 2>;
};

&mdss_dsi1_phy {
	vdds-supply = <&vreg_l3i_0p88>;
	phy-type = <PHY_TYPE_CPHY>;

	status = "okay";
};

&pcie0 {
	vdda-supply = <&vreg_l1f_0p88>;
	vddpe-3v3-supply = <&vreg_l3g_1p2>;

	pinctrl-0 = <&pcie0_default_state>;
	pinctrl-names = "default";

	status = "okay";
};

&pcie0_phy {
	vdda-phy-supply = <&vreg_l1f_0p88>;
	vdda-pll-supply = <&vreg_l3g_1p2>;

	status = "okay";
};

&pcieport0 {
	wake-gpios = <&tlmm 104 GPIO_ACTIVE_HIGH>;
	reset-gpios = <&tlmm 102 GPIO_ACTIVE_LOW>;

	wifi@0 {
		compatible = "pci17cb,110e";
		reg = <0x10000 0x0 0x0 0x0 0x0>;
		firmware-name = "LENOVO/elden";

		vddrfacmn-supply = <&vreg_pmu_rfa_cmn>;
		vddaon-supply = <&vreg_pmu_aon_0p59>;
		vddwlcx-supply = <&vreg_pmu_wlcx_0p8>;
		vddwlmx-supply = <&vreg_pmu_wlmx_0p85>;
		vddrfa0p8-supply = <&vreg_pmu_rfa_0p8>;
		vddrfa1p2-supply = <&vreg_pmu_rfa_1p2>;
		vddrfa1p8-supply = <&vreg_pmu_rfa_1p8>;
		vddpcie0p9-supply = <&vreg_pmu_pcie_0p9>;
		vddpcie1p8-supply = <&vreg_pmu_pcie_1p8>;
	};
};

&pm8550_gpios {
	volume_up_n: volume-up-n-state {
		pins = "gpio6";
		function = "normal";
		bias-pull-up;
		input-enable;
		power-source = <1>;
	};
};

&pm8550ve_gpios {
	eusb_reset_n: eusb-reset-n-state {
		pins = "gpio6";
		function = "normal";
		bias-disable;
		power-source = <1>;
		qcom,drive-strength = <2>;
	};
};

&pmih0108_eusb2_repeater {
	vdd18-supply = <&vreg_l15b_1p8>;
	vdd3-supply = <&vreg_l5b_3p1>;
};

&pon_pwrkey {
	status = "okay";
};

&pon_resin {
	linux,code = <KEY_VOLUMEDOWN>;

	status = "okay";
};

&q6apmbedai {
	#address-cells = <1>;
	#size-cells = <0>;

	dai@12 {
		reg = <SECONDARY_MI2S_RX>;
		clocks = <&q6prmcc LPASS_CLK_ID_SEC_MI2S_IBIT LPASS_CLK_ATTRIBUTE_COUPLE_NO>;
		clock-names = "bclk";
	};
};

&qupv3_1 {
	status = "okay";
};

&qupv3_2 {
	status = "okay";
};

&remoteproc_adsp {
	firmware-name = "qcom/sm8750/LENOVO/elden/adsp.mbn",
			"qcom/sm8750/LENOVO/elden/adsp_dtb.mbn";

	status = "okay";
};

&remoteproc_cdsp {
	firmware-name = "qcom/sm8750/LENOVO/elden/cdsp.mbn",
			"qcom/sm8750/LENOVO/elden/cdsp_dtb.mbn";

	status = "okay";
};

&spi4 {
	status = "okay";

	touchscreen@0 {
		compatible = "novatek,nt36536-ts-spi";
		reg = <0>;

		pinctrl-names = "default";
		pinctrl-0 = <&touch_irq_default>;

		irq-gpios = <&tlmm 162 GPIO_ACTIVE_LOW>;
		panel = <&panel>;
		spi-max-frequency = <10000000>;
		novatek,pen-support;
		firmware-name = "novatek/novatek_nt36536_lenovo_elden_csot.bin";
		touchscreen-size-x = <19040>;
		touchscreen-size-y = <30400>;
	};
};

&sdhc_2 {
	cd-gpios = <&tlmm 55 GPIO_ACTIVE_HIGH>;

	vmmc-supply = <&vreg_l9b_2p9>;
	vqmmc-supply = <&vreg_l8b_1p8>;

	no-sdio;
	no-mmc;

	pinctrl-0 = <&sdc2_default &sdc2_card_det_n>;
	pinctrl-1 = <&sdc2_sleep &sdc2_card_det_n>;
	pinctrl-names = "default", "sleep";

	status = "okay";
};

&swr1 {
	status = "okay";

	wcd_rx: codec@0,4 {
		compatible = "sdw20217010e00";
		reg = <0 4>;
		qcom,rx-port-mapping = <1 2 3 4 5 9>;
	};
};

&swr2 {
	status = "okay";

	wcd_tx: codec@0,3 {
		compatible = "sdw20217010e00";
		reg = <0 3>;
		qcom,tx-port-mapping = <2 2 3 4>;
	};
};

&tlmm {
	/* For CDT: <32 3> <37 2> <77 1>; */
	/* reserved for secure world */
	gpio-reserved-ranges = <39 1>, <74 1>;

	wcd_default: wcd-reset-n-state {
		pins = "gpio101";
		function = "gpio";
		drive-strength = <16>;
		bias-disable;
	};

	aw99706_bl_active: aw99706-bl-active-state {
		pins = "gpio88";
		function = "gpio";
		drive-strength = <8>;
		bias-disable;
	};

	bt_default: bt-default-state {
		sw-ctrl-pins {
			pins = "gpio18";
			function = "gpio";
			bias-pull-down;
		};
	};

	disp0_reset_n_active: disp0-reset-n-active-state {
		pins = "gpio98";
		function = "gpio";
		drive-strength = <8>;
		bias-disable;
	};

	disp0_reset_n_suspend: disp0-reset-n-suspend-state {
		pins = "gpio98";
		function = "gpio";
		drive-strength = <2>;
		bias-pull-down;
	};

	eusb_mux_default: eusb-mux-default-state {
		pins = "gpio29";
		function = "gpio";
		drive-strength = <2>;
		output-high; /* Unconditionally enable */
		bias-pull-down;
	};

	haptics_left_default: haptics-left-default-state {
		pins = "gpio99", "gpio127";
		function = "gpio";
		drive-strength = <2>;
		bias-pull-up;
	};

	haptics_right_default: haptics-right-default-state {
		pins = "gpio95", "gpio119";
		function = "gpio";
		drive-strength = <2>;
		bias-pull-up;
	};

	i2s1_default: i2s1-default-state {
		sck-pins {
			pins = "gpio121";
			function = "i2s1_sck";
			drive-strength = <8>;
			bias-disable;
		};

		ws-pins {
			pins = "gpio123";
			function = "i2s1_ws";
			drive-strength = <8>;
			bias-disable;
		};

		data1-pins {
			pins = "gpio124";
			function = "i2s1_data1";
			drive-strength = <8>;
			bias-disable;
		};
	};

	vddio_reg_en: vddio-reg-en-state {
		pins = "gpio161";
		function = "gpio";
		drive-strength = <8>;
		bias-pull-up;
	};

	mdp_vsync_active: mdp-vsync-active-state {
		pins = "gpio86";
		function = "mdp_vsync";
		drive-strength = <2>;
		bias-pull-down;
	};

	mdp_vsync_suspend: mdp-vsync-suspend-state {
		pins = "gpio86";
		function = "mdp_vsync";
		drive-strength = <2>;
		bias-pull-down;
	};

	sdc2_card_det_n: sd-card-det-n-state {
		pins = "gpio55";
		function = "gpio";
		drive-strength = <2>;
		bias-pull-up;
	};

	touch_irq_default: touch-irq-default-state {
		pins = "gpio162";
		function = "gpio";
		drive-strength = <8>;
		bias-pull-up;
		input-enable;
	};

	vsp_reg_en: vsp-reg-en-state {
		pins = "gpio72";
		function = "gpio";
		drive-strength = <16>;
		bias-pull-up;
	};

	vsn_reg_en: vsn-reg-en-state {
		pins = "gpio73";
		function = "gpio";
		drive-strength = <16>;
		bias-pull-up;
	};

	wlan_en: wlan-en-state {
		pins = "gpio16";
		function = "gpio";
		drive-strength = <4>;
		bias-pull-down;
		output-low;
	};
};

&uart14 {
	status = "okay";

	bluetooth {
		compatible = "qcom,wcn7860-bt";
		/*
		 * Use the vendor TLV rather than ELF: the current btqca driver
		 * keeps TLV download mode for an explicit rampatch name and
		 * selects ELF mode only for the default WCN7860 filename.
		 */
		firmware-name = "LENOVO/elden/brhbtnv20.bin",
				"LENOVO/elden/brhbtfw20.tlv";

		vddrfacmn-supply = <&vreg_pmu_rfa_cmn>;
		vddaon-supply = <&vreg_pmu_aon_0p59>;
		vddwlcx-supply = <&vreg_pmu_wlcx_0p8>;
		vddwlmx-supply = <&vreg_pmu_wlmx_0p85>;
		vddrfa0p8-supply = <&vreg_pmu_rfa_0p8>;
		vddrfa1p2-supply = <&vreg_pmu_rfa_1p2>;
		vddrfa1p8-supply = <&vreg_pmu_rfa_1p8>;

		max-speed = <3200000>;
	};
};

&ufs_mem_phy {
	vdda-phy-supply = <&vreg_l1j_0p91>;
	vdda-pll-supply = <&vreg_l3g_1p2>;

	status = "okay";
};

&ufs_mem_hc {
	reset-gpios = <&tlmm 215 GPIO_ACTIVE_LOW>;

	vcc-supply = <&vreg_l17b_2p5>;
	vcc-max-microamp = <1300000>;
	vccq-supply = <&vreg_l1d_1p2>;
	vccq-max-microamp = <1200000>;

	status = "okay";
};

&usb {
	dr_mode = "otg";
	maximum-speed = "super-speed-plus-gen2x1";

	status = "okay";

	ports {
		/*
		 * USB2.0 is shared for two ports, set pinctrl eusb_mux_default
		 * to select the repeter. Plugging out one of them will reset
		 * the DWC3, which causes both of them to be disconnected.
		 */
		port@0 {
			reg = <0>;

			usb_dwc3_hs: endpoint {
				remote-endpoint = <&pmic_glink_hs_in>;
			};
		};

		port@2 {
			reg = <2>;

			usb_dwc3_hs2: endpoint {
				remote-endpoint = <&pmic_glink_hs_c2_in>;
			};
		};
	};
};

&usb_dp_qmpphy {
	vdda-phy-supply = <&vreg_l3g_1p2>;
	vdda-pll-supply = <&vreg_l2d_0p88>;

	mode-switch;
	orientation-switch;

	status = "okay";
};

&usb_dp_qmpphy_dp_in {
	remote-endpoint = <&mdss_dp0_out>;
};

&usb_dp_qmpphy_out {
	remote-endpoint = <&pmic_glink_ss_in>;
};

&usb_hsphy {
	vdd-supply = <&vreg_l2d_0p88>;
	vdda12-supply = <&vreg_l3g_1p2>;

	phys = <&eusb_repeater>;

	status = "okay";
};

/*
 * Drop the CPU policy added by the common CPU thermal cooling patch.
 * Preserve the inherited sensors and hot/critical protection trips.
 */
&{/thermal-zones} {
	cpu-0-0-0-thermal {
		/delete-property/ polling-delay-passive;
		/delete-node/ cooling-maps;

		trips {
			/delete-node/ trip-point0;
			/delete-node/ trip-point1;
		};
	};

	cpu-0-0-1-thermal {
		/delete-property/ polling-delay-passive;
		/delete-node/ cooling-maps;

		trips {
			/delete-node/ trip-point0;
			/delete-node/ trip-point1;
		};
	};

	cpu-0-1-0-thermal {
		/delete-property/ polling-delay-passive;
		/delete-node/ cooling-maps;

		trips {
			/delete-node/ trip-point0;
			/delete-node/ trip-point1;
		};
	};

	cpu-0-1-1-thermal {
		/delete-property/ polling-delay-passive;
		/delete-node/ cooling-maps;

		trips {
			/delete-node/ trip-point0;
			/delete-node/ trip-point1;
		};
	};

	cpu-0-2-0-thermal {
		/delete-property/ polling-delay-passive;
		/delete-node/ cooling-maps;

		trips {
			/delete-node/ trip-point0;
			/delete-node/ trip-point1;
		};
	};

	cpu-0-2-1-thermal {
		/delete-property/ polling-delay-passive;
		/delete-node/ cooling-maps;

		trips {
			/delete-node/ trip-point0;
			/delete-node/ trip-point1;
		};
	};

	cpu-0-3-0-thermal {
		/delete-property/ polling-delay-passive;
		/delete-node/ cooling-maps;

		trips {
			/delete-node/ trip-point0;
			/delete-node/ trip-point1;
		};
	};

	cpu-0-3-1-thermal {
		/delete-property/ polling-delay-passive;
		/delete-node/ cooling-maps;

		trips {
			/delete-node/ trip-point0;
			/delete-node/ trip-point1;
		};
	};

	cpu-0-4-0-thermal {
		/delete-property/ polling-delay-passive;
		/delete-node/ cooling-maps;

		trips {
			/delete-node/ trip-point0;
			/delete-node/ trip-point1;
		};
	};

	cpu-0-4-1-thermal {
		/delete-property/ polling-delay-passive;
		/delete-node/ cooling-maps;

		trips {
			/delete-node/ trip-point0;
			/delete-node/ trip-point1;
		};
	};

	cpu-0-5-0-thermal {
		/delete-property/ polling-delay-passive;
		/delete-node/ cooling-maps;

		trips {
			/delete-node/ trip-point0;
			/delete-node/ trip-point1;
		};
	};

	cpu-0-5-1-thermal {
		/delete-property/ polling-delay-passive;
		/delete-node/ cooling-maps;

		trips {
			/delete-node/ trip-point0;
			/delete-node/ trip-point1;
		};
	};

	cpu-1-0-0-thermal {
		/delete-property/ polling-delay-passive;
		/delete-node/ cooling-maps;

		trips {
			/delete-node/ trip-point0;
			/delete-node/ trip-point1;
		};
	};

	cpu-1-0-1-thermal {
		/delete-property/ polling-delay-passive;
		/delete-node/ cooling-maps;

		trips {
			/delete-node/ trip-point0;
			/delete-node/ trip-point1;
		};
	};

	cpu-1-1-0-thermal {
		/delete-property/ polling-delay-passive;
		/delete-node/ cooling-maps;

		trips {
			/delete-node/ trip-point0;
			/delete-node/ trip-point1;
		};
	};

	cpu-1-1-1-thermal {
		/delete-property/ polling-delay-passive;
		/delete-node/ cooling-maps;

		trips {
			/delete-node/ trip-point0;
			/delete-node/ trip-point1;
		};
	};
};

/*
 * lenovo,elden CPU/GPU policy, following h0cheung's TB322FC device tree.
 */
&{/thermal-zones} {
	cpu-0-0-0-thermal {
		polling-delay-passive = <100>;

		trips {
			cpu_0_0_0_passive: passive {
				temperature = <105000>;
				hysteresis = <5000>;
				type = "passive";
			};
		};

		cooling-maps {
			map0 {
				trip = <&cpu_0_0_0_passive>;
				cooling-device = <&cpu0 THERMAL_NO_LIMIT THERMAL_NO_LIMIT>;
			};
		};
	};

	cpu-0-0-1-thermal {
		polling-delay-passive = <100>;

		trips {
			cpu_0_0_1_passive: passive {
				temperature = <105000>;
				hysteresis = <5000>;
				type = "passive";
			};
		};

		cooling-maps {
			map0 {
				trip = <&cpu_0_0_1_passive>;
				cooling-device = <&cpu0 THERMAL_NO_LIMIT THERMAL_NO_LIMIT>;
			};
		};
	};

	cpu-0-1-0-thermal {
		polling-delay-passive = <100>;

		trips {
			cpu_0_1_0_passive: passive {
				temperature = <105000>;
				hysteresis = <5000>;
				type = "passive";
			};
		};

		cooling-maps {
			map0 {
				trip = <&cpu_0_1_0_passive>;
				cooling-device = <&cpu0 THERMAL_NO_LIMIT THERMAL_NO_LIMIT>;
			};
		};
	};

	cpu-0-1-1-thermal {
		polling-delay-passive = <100>;

		trips {
			cpu_0_1_1_passive: passive {
				temperature = <105000>;
				hysteresis = <5000>;
				type = "passive";
			};
		};

		cooling-maps {
			map0 {
				trip = <&cpu_0_1_1_passive>;
				cooling-device = <&cpu0 THERMAL_NO_LIMIT THERMAL_NO_LIMIT>;
			};
		};
	};

	cpu-0-2-0-thermal {
		polling-delay-passive = <100>;

		trips {
			cpu_0_2_0_passive: passive {
				temperature = <105000>;
				hysteresis = <5000>;
				type = "passive";
			};
		};

		cooling-maps {
			map0 {
				trip = <&cpu_0_2_0_passive>;
				cooling-device = <&cpu0 THERMAL_NO_LIMIT THERMAL_NO_LIMIT>;
			};
		};
	};

	cpu-0-2-1-thermal {
		polling-delay-passive = <100>;

		trips {
			cpu_0_2_1_passive: passive {
				temperature = <105000>;
				hysteresis = <5000>;
				type = "passive";
			};
		};

		cooling-maps {
			map0 {
				trip = <&cpu_0_2_1_passive>;
				cooling-device = <&cpu0 THERMAL_NO_LIMIT THERMAL_NO_LIMIT>;
			};
		};
	};

	cpu-0-3-0-thermal {
		polling-delay-passive = <100>;

		trips {
			cpu_0_3_0_passive: passive {
				temperature = <105000>;
				hysteresis = <5000>;
				type = "passive";
			};
		};

		cooling-maps {
			map0 {
				trip = <&cpu_0_3_0_passive>;
				cooling-device = <&cpu0 THERMAL_NO_LIMIT THERMAL_NO_LIMIT>;
			};
		};
	};

	cpu-0-3-1-thermal {
		polling-delay-passive = <100>;

		trips {
			cpu_0_3_1_passive: passive {
				temperature = <105000>;
				hysteresis = <5000>;
				type = "passive";
			};
		};

		cooling-maps {
			map0 {
				trip = <&cpu_0_3_1_passive>;
				cooling-device = <&cpu0 THERMAL_NO_LIMIT THERMAL_NO_LIMIT>;
			};
		};
	};

	cpu-0-4-0-thermal {
		polling-delay-passive = <100>;

		trips {
			cpu_0_4_0_passive: passive {
				temperature = <105000>;
				hysteresis = <5000>;
				type = "passive";
			};
		};

		cooling-maps {
			map0 {
				trip = <&cpu_0_4_0_passive>;
				cooling-device = <&cpu0 THERMAL_NO_LIMIT THERMAL_NO_LIMIT>;
			};
		};
	};

	cpu-0-4-1-thermal {
		polling-delay-passive = <100>;

		trips {
			cpu_0_4_1_passive: passive {
				temperature = <105000>;
				hysteresis = <5000>;
				type = "passive";
			};
		};

		cooling-maps {
			map0 {
				trip = <&cpu_0_4_1_passive>;
				cooling-device = <&cpu0 THERMAL_NO_LIMIT THERMAL_NO_LIMIT>;
			};
		};
	};

	cpu-0-5-0-thermal {
		polling-delay-passive = <100>;

		trips {
			cpu_0_5_0_passive: passive {
				temperature = <105000>;
				hysteresis = <5000>;
				type = "passive";
			};
		};

		cooling-maps {
			map0 {
				trip = <&cpu_0_5_0_passive>;
				cooling-device = <&cpu0 THERMAL_NO_LIMIT THERMAL_NO_LIMIT>;
			};
		};
	};

	cpu-0-5-1-thermal {
		polling-delay-passive = <100>;

		trips {
			cpu_0_5_1_passive: passive {
				temperature = <105000>;
				hysteresis = <5000>;
				type = "passive";
			};
		};

		cooling-maps {
			map0 {
				trip = <&cpu_0_5_1_passive>;
				cooling-device = <&cpu0 THERMAL_NO_LIMIT THERMAL_NO_LIMIT>;
			};
		};
	};

	cpu-1-0-0-thermal {
		polling-delay-passive = <100>;

		trips {
			cpu_1_0_0_passive: passive {
				temperature = <105000>;
				hysteresis = <5000>;
				type = "passive";
			};
		};

		cooling-maps {
			map0 {
				trip = <&cpu_1_0_0_passive>;
				cooling-device = <&cpu6 THERMAL_NO_LIMIT THERMAL_NO_LIMIT>;
			};
		};
	};

	cpu-1-0-1-thermal {
		polling-delay-passive = <100>;

		trips {
			cpu_1_0_1_passive: passive {
				temperature = <105000>;
				hysteresis = <5000>;
				type = "passive";
			};
		};

		cooling-maps {
			map0 {
				trip = <&cpu_1_0_1_passive>;
				cooling-device = <&cpu6 THERMAL_NO_LIMIT THERMAL_NO_LIMIT>;
			};
		};
	};

	cpu-1-1-0-thermal {
		polling-delay-passive = <100>;

		trips {
			cpu_1_1_0_passive: passive {
				temperature = <105000>;
				hysteresis = <5000>;
				type = "passive";
			};
		};

		cooling-maps {
			map0 {
				trip = <&cpu_1_1_0_passive>;
				cooling-device = <&cpu6 THERMAL_NO_LIMIT THERMAL_NO_LIMIT>;
			};
		};
	};

	cpu-1-1-1-thermal {
		polling-delay-passive = <100>;

		trips {
			cpu_1_1_1_passive: passive {
				temperature = <105000>;
				hysteresis = <5000>;
				type = "passive";
			};
		};

		cooling-maps {
			map0 {
				trip = <&cpu_1_1_1_passive>;
				cooling-device = <&cpu6 THERMAL_NO_LIMIT THERMAL_NO_LIMIT>;
			};
		};
	};

	gpuss0-thermal {
		polling-delay-passive = <100>;

		trips {
			gpuss0_passive: passive {
				temperature = <105000>;
				hysteresis = <5000>;
				type = "passive";
			};
		};

		cooling-maps {
			map0 {
				trip = <&gpuss0_passive>;
				cooling-device = <&gpu THERMAL_NO_LIMIT THERMAL_NO_LIMIT>;
			};
		};
	};

	gpuss1-thermal {
		polling-delay-passive = <100>;

		trips {
			gpuss1_passive: passive {
				temperature = <105000>;
				hysteresis = <5000>;
				type = "passive";
			};
		};

		cooling-maps {
			map0 {
				trip = <&gpuss1_passive>;
				cooling-device = <&gpu THERMAL_NO_LIMIT THERMAL_NO_LIMIT>;
			};
		};
	};

	gpuss2-thermal {
		polling-delay-passive = <100>;

		trips {
			gpuss2_passive: passive {
				temperature = <105000>;
				hysteresis = <5000>;
				type = "passive";
			};
		};

		cooling-maps {
			map0 {
				trip = <&gpuss2_passive>;
				cooling-device = <&gpu THERMAL_NO_LIMIT THERMAL_NO_LIMIT>;
			};
		};
	};

	gpuss3-thermal {
		polling-delay-passive = <100>;

		trips {
			gpuss3_passive: passive {
				temperature = <105000>;
				hysteresis = <5000>;
				type = "passive";
			};
		};

		cooling-maps {
			map0 {
				trip = <&gpuss3_passive>;
				cooling-device = <&gpu THERMAL_NO_LIMIT THERMAL_NO_LIMIT>;
			};
		};
	};

	gpuss4-thermal {
		polling-delay-passive = <100>;

		trips {
			gpuss4_passive: passive {
				temperature = <105000>;
				hysteresis = <5000>;
				type = "passive";
			};
		};

		cooling-maps {
			map0 {
				trip = <&gpuss4_passive>;
				cooling-device = <&gpu THERMAL_NO_LIMIT THERMAL_NO_LIMIT>;
			};
		};
	};

	gpuss5-thermal {
		polling-delay-passive = <100>;

		trips {
			gpuss5_passive: passive {
				temperature = <105000>;
				hysteresis = <5000>;
				type = "passive";
			};
		};

		cooling-maps {
			map0 {
				trip = <&gpuss5_passive>;
				cooling-device = <&gpu THERMAL_NO_LIMIT THERMAL_NO_LIMIT>;
			};
		};
	};

	gpuss6-thermal {
		polling-delay-passive = <100>;

		trips {
			gpuss6_passive: passive {
				temperature = <105000>;
				hysteresis = <5000>;
				type = "passive";
			};
		};

		cooling-maps {
			map0 {
				trip = <&gpuss6_passive>;
				cooling-device = <&gpu THERMAL_NO_LIMIT THERMAL_NO_LIMIT>;
			};
		};
	};

	gpuss7-thermal {
		polling-delay-passive = <100>;

		trips {
			gpuss7_passive: passive {
				temperature = <105000>;
				hysteresis = <5000>;
				type = "passive";
			};
		};

		cooling-maps {
			map0 {
				trip = <&gpuss7_passive>;
				cooling-device = <&gpu THERMAL_NO_LIMIT THERMAL_NO_LIMIT>;
			};
		};
	};
};
